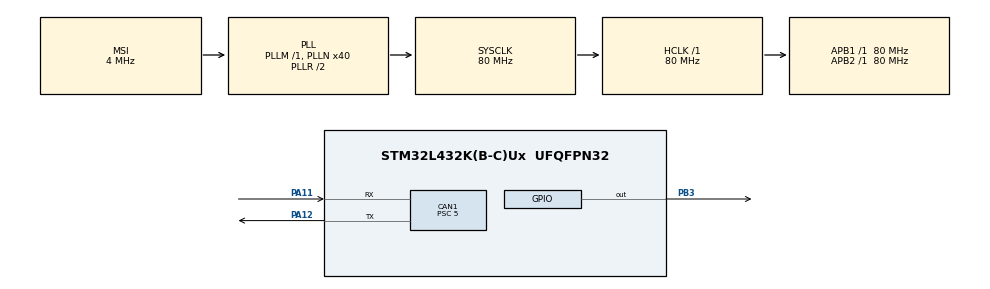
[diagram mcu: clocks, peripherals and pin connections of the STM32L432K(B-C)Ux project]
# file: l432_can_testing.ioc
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CAN1.BS1=CAN_BS1_9TQ
CAN1.BS2=CAN_BS2_6TQ
CAN1.CalculateTimeBit=1000
CAN1.CalculateTimeQuantum=62.5
CAN1.Prescaler=5
Mcu.Family=STM32L4
Mcu.Name=STM32L432K(B-C)Ux
Mcu.Package=UFQFPN32
NVIC.PriorityGroup=NVIC_PRIORITYGROUP_4
PA11.Mode=Master
PA11.Signal=CAN1_RX
PA12.Mode=Master
PA12.Signal=CAN1_TX
PB3\ (JTDO-TRACESWO).Signal=GPIO_Output
ProjectManager.HeapSize=0x200
ProjectManager.StackSize=0x400
ProjectManager.TargetToolchain=Makefile
RCC.AHBFreq_Value=80000000
RCC.APB1Freq_Value=80000000
RCC.APB1TimFreq_Value=80000000
RCC.APB2Freq_Value=80000000
RCC.APB2TimFreq_Value=80000000
RCC.CortexFreq_Value=80000000
RCC.HCLKFreq_Value=80000000
RCC.HSE_VALUE=8000000
RCC.HSI48_VALUE=48000000
RCC.HSI_VALUE=16000000
RCC.LSE_VALUE=32768
RCC.MSI_VALUE=4000000
RCC.PLLN=40
RCC.SYSCLKFreq_VALUE=80000000
RCC.SYSCLKSource=RCC_SYSCLKSOURCE_PLLCLK
RCC.VCOOutputFreq_Value=160000000
board=l432_can_testing

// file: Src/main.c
/**
  ******************************************************************************
  * File Name          : main.c
  * Description        : Main program body
  ******************************************************************************
  ** This notice applies to any and all portions of this file
  * that are not between comment pairs USER CODE BEGIN and
  * USER CODE END. Other portions of this file, whether
  * inserted by the user or by software development tools
  * are owned by their respective copyright owners.
  *
  * COPYRIGHT(c) 2017 STMicroelectronics
  *
  * Redistribution and use in source and binary forms, with or without modification,
  * are permitted provided that the following conditions are met:
  *   1. Redistributions of source code must retain the above copyright notice,
  *      this list of conditions and the following disclaimer.
  *   2. Redistributions in binary form must reproduce the above copyright notice,
  *      this list of conditions and the following disclaimer in the documentation
  *      and/or other materials provided with the distribution.
  *   3. Neither the name of STMicroelectronics nor the names of its contributors
  *      may be used to endorse or promote products derived from this software
  *      without specific prior written permission.
  *
  * THIS SOFTWARE IS PROVIDED BY THE COPYRIGHT HOLDERS AND CONTRIBUTORS "AS IS"
  * AND ANY EXPRESS OR IMPLIED WARRANTIES, INCLUDING, BUT NOT LIMITED TO, THE
  * IMPLIED WARRANTIES OF MERCHANTABILITY AND FITNESS FOR A PARTICULAR PURPOSE ARE
  * DISCLAIMED. IN NO EVENT SHALL THE COPYRIGHT HOLDER OR CONTRIBUTORS BE LIABLE
  * FOR ANY DIRECT, INDIRECT, INCIDENTAL, SPECIAL, EXEMPLARY, OR CONSEQUENTIAL
  * DAMAGES (INCLUDING, BUT NOT LIMITED TO, PROCUREMENT OF SUBSTITUTE GOODS OR
  * SERVICES; LOSS OF USE, DATA, OR PROFITS; OR BUSINESS INTERRUPTION) HOWEVER
  * CAUSED AND ON ANY THEORY OF LIABILITY, WHETHER IN CONTRACT, STRICT LIABILITY,
  * OR TORT (INCLUDING NEGLIGENCE OR OTHERWISE) ARISING IN ANY WAY OUT OF THE USE
  * OF THIS SOFTWARE, EVEN IF ADVISED OF THE POSSIBILITY OF SUCH DAMAGE.
  *
  ******************************************************************************
  */
#include "main.h"
#include "stm32l4xx_hal.h"

CAN_HandleTypeDef hcan1;

/* USER CODE BEGIN PV */
/* Private variables ---------------------------------------------------------*/

/* USER CODE END PV */

void SystemClock_Config(void);
static void MX_GPIO_Init(void);
static void MX_CAN1_Init(void);

/* USER CODE BEGIN PFP */
/* Private function prototypes -----------------------------------------------*/

/* USER CODE END PFP */

int main(void)
{

  /* MCU Configuration----------------------------------------------------------*/

  /* Reset of all peripherals, Initializes the Flash interface and the Systick. */
  HAL_Init();

  /* Configure the system clock */
  SystemClock_Config();

  /* Initialize all configured peripherals */
  MX_GPIO_Init();
  MX_CAN1_Init();

  /* USER CODE BEGIN 2 */
  static CanTxMsgTypeDef TxMessage;
  static CanRxMsgTypeDef RxMessage;
  hcan1.pTxMsg = &TxMessage;
  hcan1.pRxMsg = &RxMessage;

  hcan1.pTxMsg->ExtId = 0x1112;
  hcan1.pTxMsg->IDE = CAN_ID_EXT;
  hcan1.pTxMsg->RTR = CAN_RTR_DATA;
  hcan1.pTxMsg->DLC = 1;
  hcan1.pTxMsg->Data[0] = 12;

  /* USER CODE END 2 */

  /* Infinite loop */
  /* USER CODE BEGIN WHILE */
  uint8_t count = 0;
  while (1)
  {
    HAL_CAN_Transmit(&hcan1, 3000);
    hcan1.pTxMsg->Data[0] = count;
    HAL_GPIO_TogglePin(GPIOB, GPIO_PIN_3);
    count++;
    HAL_Delay(10);
  /* USER CODE END WHILE */

  }

}

/** System Clock Configuration
*/
void SystemClock_Config(void)
{

  RCC_OscInitTypeDef RCC_OscInitStruct;
  RCC_ClkInitTypeDef RCC_ClkInitStruct;

    /**Initializes the CPU, AHB and APB busses clocks
    */
  RCC_OscInitStruct.OscillatorType = RCC_OSCILLATORTYPE_MSI;
  RCC_OscInitStruct.MSIState = RCC_MSI_ON;
  RCC_OscInitStruct.MSICalibrationValue = 0;
  RCC_OscInitStruct.MSIClockRange = RCC_MSIRANGE_6;
  RCC_OscInitStruct.PLL.PLLState = RCC_PLL_ON;
  RCC_OscInitStruct.PLL.PLLSource = RCC_PLLSOURCE_MSI;
  RCC_OscInitStruct.PLL.PLLM = 1;
  RCC_OscInitStruct.PLL.PLLN = 40;
  RCC_OscInitStruct.PLL.PLLP = RCC_PLLP_DIV7;
  RCC_OscInitStruct.PLL.PLLQ = RCC_PLLQ_DIV2;
  RCC_OscInitStruct.PLL.PLLR = RCC_PLLR_DIV2;
  if (HAL_RCC_OscConfig(&RCC_OscInitStruct) != HAL_OK)
  {
    _Error_Handler(__FILE__, __LINE__);
  }

    /**Initializes the CPU, AHB and APB busses clocks
    */
  RCC_ClkInitStruct.ClockType = RCC_CLOCKTYPE_HCLK|RCC_CLOCKTYPE_SYSCLK
                              |RCC_CLOCKTYPE_PCLK1|RCC_CLOCKTYPE_PCLK2;
  RCC_ClkInitStruct.SYSCLKSource = RCC_SYSCLKSOURCE_PLLCLK;
  RCC_ClkInitStruct.AHBCLKDivider = RCC_SYSCLK_DIV1;
  RCC_ClkInitStruct.APB1CLKDivider = RCC_HCLK_DIV1;
  RCC_ClkInitStruct.APB2CLKDivider = RCC_HCLK_DIV1;

  if (HAL_RCC_ClockConfig(&RCC_ClkInitStruct, FLASH_LATENCY_4) != HAL_OK)
  {
    _Error_Handler(__FILE__, __LINE__);
  }

    /**Configure the main internal regulator output voltage
    */
  if (HAL_PWREx_ControlVoltageScaling(PWR_REGULATOR_VOLTAGE_SCALE1) != HAL_OK)
  {
    _Error_Handler(__FILE__, __LINE__);
  }

    /**Configure the Systick interrupt time
    */
  HAL_SYSTICK_Config(HAL_RCC_GetHCLKFreq()/1000);

    /**Configure the Systick
    */
  HAL_SYSTICK_CLKSourceConfig(SYSTICK_CLKSOURCE_HCLK);

  /* SysTick_IRQn interrupt configuration */
  HAL_NVIC_SetPriority(SysTick_IRQn, 0, 0);
}

/* CAN1 init function */
static void MX_CAN1_Init(void)
{

  hcan1.Instance = CAN1;
  hcan1.Init.Prescaler = 5;
  hcan1.Init.Mode = CAN_MODE_NORMAL;
  hcan1.Init.SJW = CAN_SJW_1TQ;
  hcan1.Init.BS1 = CAN_BS1_9TQ;
  hcan1.Init.BS2 = CAN_BS2_6TQ;
  hcan1.Init.TTCM = DISABLE;
  hcan1.Init.ABOM = DISABLE;
  hcan1.Init.AWUM = DISABLE;
  hcan1.Init.NART = DISABLE;
  hcan1.Init.RFLM = DISABLE;
  hcan1.Init.TXFP = DISABLE;
  if (HAL_CAN_Init(&hcan1) != HAL_OK)
  {
    _Error_Handler(__FILE__, __LINE__);
  }

}

/** Configure pins as
        * Analog
        * Input
        * Output
        * EVENT_OUT
        * EXTI
*/
static void MX_GPIO_Init(void)
{

  GPIO_InitTypeDef GPIO_InitStruct;

  /* GPIO Ports Clock Enable */
  __HAL_RCC_GPIOA_CLK_ENABLE();
  __HAL_RCC_GPIOB_CLK_ENABLE();

  /*Configure GPIO pin Output Level */
  HAL_GPIO_WritePin(GPIOB, GPIO_PIN_3, GPIO_PIN_RESET);

  /*Configure GPIO pin : PB3 */
  GPIO_InitStruct.Pin = GPIO_PIN_3;
  GPIO_InitStruct.Mode = GPIO_MODE_OUTPUT_PP;
  GPIO_InitStruct.Pull = GPIO_NOPULL;
  GPIO_InitStruct.Speed = GPIO_SPEED_FREQ_LOW;
  HAL_GPIO_Init(GPIOB, &GPIO_InitStruct);

}

void _Error_Handler(char * file, int line)
{
  while(1)
  {
  }
}

/************************ (C) COPYRIGHT STMicroelectronics *****END OF FILE****/
